# CM_CORE_AON__MPU register map
Vendor: Texas Instruments
Peripheral module from a debugger description file (folder TDA2Px).
Registers are 32-bit, access per field, reset 0x0 unless marked. A register's access mark holds for its fields unless they carry their own. Offsets are as the file gives them; lines under a group give offsets from that group; [hi:lo] are bit positions; {n}, {i} and the like mark numbered series; 'fields as' and 'values as' point back to an identical list; <NAME> marks a mode.

## CM_CORE_AON__MPU
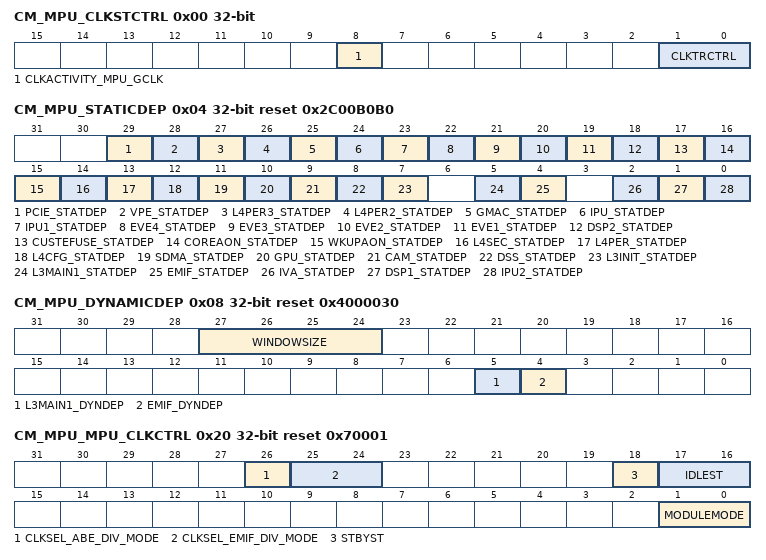
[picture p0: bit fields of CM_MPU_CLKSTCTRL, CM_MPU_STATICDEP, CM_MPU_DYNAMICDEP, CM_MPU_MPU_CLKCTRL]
0x00 CM_MPU_CLKSTCTRL — This register enables the MPU domain power state transition. It controls the HW supervised domain power state transition between ON-ACTIVE and ON-INACTIVE states. It also hold one status bit per clock input of the domain.
  [8] CLKACTIVITY_MPU_GCLK ro — This field indicates the state of the MPU_DPLL_CLK clock in the domain. [warm reset insensitive]
    0=INACT (Corresponding clock is definitely gated); 1=ACT (Corresponding clock is running or gating/ungating transition is on-going)
  [1:0] CLKTRCTRL rw — Controls the clock state transition of the MPU clock domain.
    0=NO_SLEEP (NO_SLEEP: Sleep transition cannot be initiated. Wakeup transition may however occur.); 2=SW_WKUP (SW_WKUP: Start a software forced wake-up transition on the domain.); 3=HW_AUTO (HW_AUTO: Automatic transition is enabled. Sleep and wakeup transition are based upon hardware conditions.)
0x04 CM_MPU_STATICDEP reset 0x2C00B0B0 — This register controls the static domain depedencies from MPU domain towards 'target' domains. It is relevant only for domain having system initiator(s).
  [29] PCIE_STATDEP rw — Static dependency towards PCIE clock domain
    0=DISABLED (Dependency is disabled); 1=ENABLED (Dependency is enabled)
  [28] VPE_STATDEP rw — Static dependency towards VPE clock domain
    0=Dependency_is_disabled; 1=Dependency_is_enabled
  [27] L4PER3_STATDEP rw — Static dependency towards L4PER3 clock domain
    values as PCIE_STATDEP
  [26] L4PER2_STATDEP rw — Static dependency towards L4PER2 clock domain
    values as PCIE_STATDEP
  [25] GMAC_STATDEP rw — Static dependency towards GMAC clock domain
    values as PCIE_STATDEP
  [24] IPU_STATDEP rw — Static dependency towards IPU clock domain
    values as PCIE_STATDEP
  [23] IPU1_STATDEP rw — Static dependency towards IPU1 clock domain
    values as PCIE_STATDEP
  [22] EVE4_STATDEP rw — Static dependency towards EVE4 clock domainEVE4 is not supported in this family of devices.
    values as PCIE_STATDEP
  [21] EVE3_STATDEP rw — Static dependency towards EVE3 clock domainEVE3 is not supported in this family of devices.
    values as PCIE_STATDEP
  [20] EVE2_STATDEP rw — Static dependency towards EVE2 clock domain
    values as PCIE_STATDEP
  [19] EVE1_STATDEP rw — Static dependency towards EVE1 clock domain
    values as PCIE_STATDEP
  [18] DSP2_STATDEP rw — Static dependency towards DSP2 clock domain
    values as PCIE_STATDEP
  [17] CUSTEFUSE_STATDEP ro — Static dependency towards CUSTEFUSE clock domain
    0=DISABLED (Dependency is disabled)
  [16] COREAON_STATDEP ro — Static dependency towards COREAON clock domain
    0=DISABLED (Dependency is disabled)
  [15] WKUPAON_STATDEP rw — Static dependency towards WKUPAON clock domain
    values as PCIE_STATDEP
  [14] L4SEC_STATDEP rw — Static dependency towards L4SEC clock domain
    values as PCIE_STATDEP
  [13] L4PER_STATDEP rw — Static dependency towards L4PER clock domain
    values as PCIE_STATDEP
  [12] L4CFG_STATDEP rw — Static dependency towards L4CFG clock domain
    values as PCIE_STATDEP
  [11] SDMA_STATDEP ro — Static dependency towards SDMA clock domain
    0=Dependency_is_disabled
  [10] GPU_STATDEP rw — Static dependency towards GPU clock domain
    values as PCIE_STATDEP
  [9] CAM_STATDEP rw — Static dependency towards CAM clock domain
    values as PCIE_STATDEP
  [8] DSS_STATDEP rw — Static dependency towards DSS clock domain
    values as PCIE_STATDEP
  [7] L3INIT_STATDEP rw — Static dependency towards L3INIT clock domain
    values as PCIE_STATDEP
  [5] L3MAIN1_STATDEP rw — Static dependency towards L3MAIN clock domain
    values as PCIE_STATDEP
  [4] EMIF_STATDEP rw — Static dependency towards EMIF clock domain
    values as PCIE_STATDEP
  [2] IVA_STATDEP rw — Static dependency towards IVA clock domain
    values as PCIE_STATDEP
  [1] DSP1_STATDEP rw — Static dependency towards DSP1 clock domain
    values as PCIE_STATDEP
  [0] IPU2_STATDEP rw — Static dependency towards IPU2 clock domain
    0=Dependency_is_disabled; 1=Dependency_is_enabled
0x08 CM_MPU_DYNAMICDEP reset 0x4000030 — This register controls the dynamic domain depedencies from MPU domain towards 'target' domains. It is relevant only for domain having OCP master port(s).
  [27:24] WINDOWSIZE rw — Size of sliding window used to monitor OCP interface activity for determination of auto-sleep feature. Time unit defined byCM_DYN_DEP_PRESCAL register.
  [5] L3MAIN1_DYNDEP ro — Dynamic dependency towards L3MAIN1 clock domain
    1=ENABLED (Dependency is enabled)
  [4] EMIF_DYNDEP ro — Dynamic dependency towards EMIF clock domain
    1=ENABLED (Dependency is enabled)
0x20 CM_MPU_MPU_CLKCTRL reset 0x70001 — This register manages the MPU clocks.
  [26] CLKSEL_ABE_DIV_MODE rw — Selects the ratio for MPU - ABE async bridge versus MPU DPLL clock
    0=DIV8 (MPU DPLL clock divided by 8); 1=DIV16 (MPU DPLL clock divided by 16)
  [25:24] CLKSEL_EMIF_DIV_MODE rw — Selects the ratio for MPU - L3 async bridge versus MPU DPLL clock
    0=DIV4A (MPU DPLL clock divided by 4); 1=DIV4 (MPU DPLL clock divided by 4); 2=DIV8 (MPU DPLL clock divided by 8); 3=DIV8B (MPU DPLL clock divided by 8)
  [18] STBYST ro — Module standby status. [warm reset insensitive]
    0=FUNC (Module is functional (not in standby)); 1=STANDBY (Module is in standby)
  [17:16] IDLEST ro — Module idle status. [warm reset insensitive]
    0=FUNC (Module is fully functional, including OCP); 1=TRANS (Module is performing transition: wakeup, or sleep, or sleep abortion); 2=IDLE (Module is in Idle mode (only OCP part). It is functional if using separate functional clock); 3=DISABLE (Module is disabled and cannot be accessed)
  [1:0] MODULEMODE ro — Control the way mandatory clocks are managed.
    1=AUTO (Module is managed automatically by HW according to clock domain transition. A clock domain sleep transition put module into idle. A wakeup domain transition put it back into function. Module clocks may be gated according to the clock domain state.)
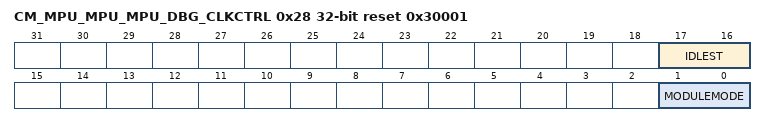
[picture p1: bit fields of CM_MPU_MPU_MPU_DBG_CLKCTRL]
0x28 CM_MPU_MPU_MPU_DBG_CLKCTRL ro reset 0x30001 — This register manages the MPU_MPU_DBG clocks. [warm reset insensitive]
  [17:16] IDLEST — Module idle status
    values as CM_MPU_MPU_CLKCTRL.IDLEST
  [1:0] MODULEMODE — Control the way mandatory clocks are managed.
    1=AUTO (Module is managed automatically by HW according to clock domain transition. A clock domain sleep transition put module into idle. A wakeup domain transition put it back into function. If CLKTRCTRL=3, any OCP access to module is always granted. Module clocks may be gated according to the clock domain state.)
